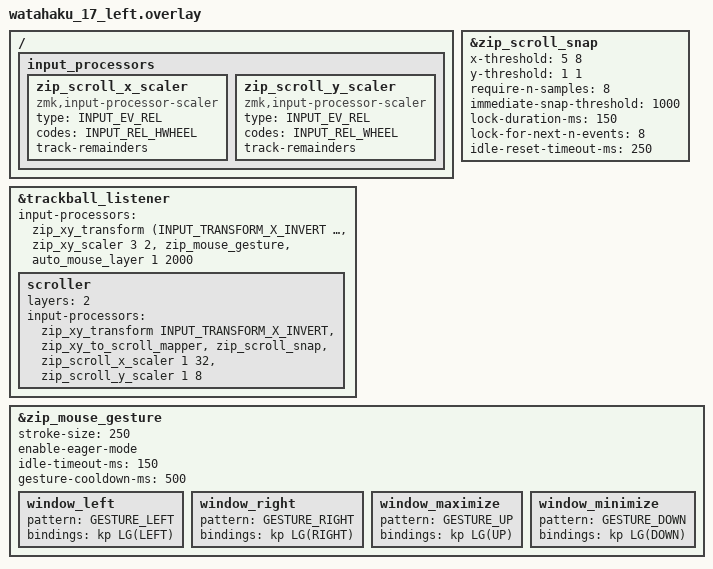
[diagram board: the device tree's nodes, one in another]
#include "watahaku_17.dtsi"
#include <input/processors.dtsi>
#include <dt-bindings/zmk/input_transform.h>
#include <zephyr/dt-bindings/input/input-event-codes.h>
#include <scroll-snap.dtsi>
#include <mouse-gesture.dtsi>

/ {
    input_processors {
        zip_scroll_x_scaler: zip_scroll_x_scaler {
            compatible = "zmk,input-processor-scaler";
            #input-processor-cells = <2>;
            type = <INPUT_EV_REL>;
            codes = <INPUT_REL_HWHEEL>;
            track-remainders;
        };

        zip_scroll_y_scaler: zip_scroll_y_scaler {
            compatible = "zmk,input-processor-scaler";
            #input-processor-cells = <2>;
            type = <INPUT_EV_REL>;
            codes = <INPUT_REL_WHEEL>;
            track-remainders;
        };
    };
};

&trackball_listener {
    // Normal mode: Balanced speed (1.5x)
    input-processors = <
        &zip_xy_transform (INPUT_TRANSFORM_X_INVERT | INPUT_TRANSFORM_Y_INVERT)
        &zip_xy_scaler 3 2  // 1.5x speed
        &zip_mouse_gesture  // Mouse gesture for window management
        &auto_mouse_layer 1 2000  // Activate layer 1 for 2 seconds on movement
    >;

    // Layer 2: Scroll mode
    scroller {
        layers = <2>;
        input-processors = <
            &zip_xy_transform INPUT_TRANSFORM_X_INVERT
            &zip_xy_to_scroll_mapper
            &zip_scroll_snap           // Snap scroll to nearest axis
            &zip_scroll_x_scaler 1 32  // X-axis: 1/32x scroll speed
            &zip_scroll_y_scaler 1 8   // Y-axis: 1/8x scroll speed
        >;
    };
};

// Customize scroll snap behavior
&zip_scroll_snap {
    x-threshold = <5 8>;           // Snap to X if |y/x| < 5/8 (0.625)
    y-threshold = <1 1>;           // Snap to Y if |y/x| > 1
    require-n-samples = <8>;       // Collect 8 samples before snapping (faster response)
    immediate-snap-threshold = <1000>;  // Snap immediately if movement exceeds 1000
    lock-duration-ms = <150>;      // Lock direction for 150ms
    lock-for-next-n-events = <8>;  // Keep direction for next 8 events
    idle-reset-timeout-ms = <250>; // Reset after 250ms idle
};

// Configure mouse gesture for window management
&zip_mouse_gesture {
    stroke-size = <250>;           // Stroke size for gesture recognition
    enable-eager-mode;             // Execute immediately when pattern matches
    idle-timeout-ms = <150>;       // Wait 150ms before executing
    gesture-cooldown-ms = <500>;   // Cooldown to prevent double gestures

    // Move window left (Win + Left)
    window_left {
        pattern = <GESTURE_LEFT>;
        bindings = <&kp LG(LEFT)>;
    };

    // Move window right (Win + Right)
    window_right {
        pattern = <GESTURE_RIGHT>;
        bindings = <&kp LG(RIGHT)>;
    };

    // Maximize window (Win + Up)
    window_maximize {
        pattern = <GESTURE_UP>;
        bindings = <&kp LG(UP)>;
    };

    // Minimize/Restore window (Win + Down)
    window_minimize {
        pattern = <GESTURE_DOWN>;
        bindings = <&kp LG(DOWN)>;
    };
};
